AUTOSAR XML (schema 00047)
package /ServiceLayer
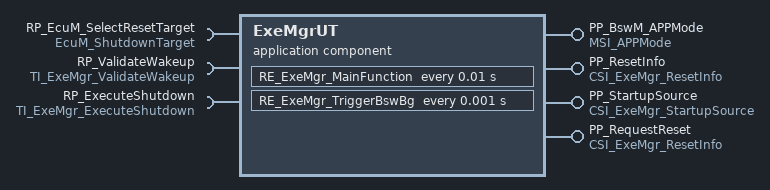
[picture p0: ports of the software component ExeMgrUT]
  application sw component type ExeMgrUT
    require port RP_EcuM_SelectResetTarget: required-interface=EcuM_ShutdownTarget
    4 x provide port:
      PP_BswM_APPMode: provided-interface=MSI_APPMode
      PP_ResetInfo: provided-interface=CSI_ExeMgr_ResetInfo
      PP_StartupSource: provided-interface=CSI_ExeMgr_StartupSource
      PP_RequestReset: provided-interface=CSI_ExeMgr_ResetInfo
    require port RP_ValidateWakeup: required-interface=TI_ExeMgr_ValidateWakeup
    require port RP_ExecuteShutdown: required-interface=TI_ExeMgr_ExecuteShutdown
    behavior IB_ExeMgrUT: data-type-mapping=[DTS_DcmEcuReset, ECUM_STATE_Mapping, ComMModeMapping]
      exclusive area ExeMgr_TriggerBswBg_EXCLUSIVE_AREA
      timing event TE_ExeMgr_MainFunction: start-on-event=RE_ExeMgr_MainFunction, period=0.01
      init event IE_ExeMgr_EvaluateWakeup: start-on-event=RE_ExeMgr_EvaluateWakeup
      init event IE_ExeMgr_EvaluateReset: start-on-event=RE_ExeMgr_EvaluateReset
      operation invoked event OIE_ExeMgr_ExecuteReset: start-on-event=RE_ExeMgr_ExecuteReset, operation=PP_RequestReset.RequestReset
      operation invoked event OIE_ExeMgr_GetLastStartupSource: start-on-event=RE_ExeMgr_StartupSource, operation=PP_StartupSource.GetLastStartupSource
      operation invoked event OIE_ExeMgr_GetLastResetInfo: start-on-event=RE_ExeMgr_ResetInfo, operation=PP_ResetInfo.GetLastResetInfo
      timing event TE_ExeMgr_TriggerBswBg: start-on-event=RE_ExeMgr_TriggerBswBg, period=0.001
      internal trigger occurred event ITE_ExeMgr_GetWakeupSource: start-on-event=RE_ExeMgr_GetWakeupSource, event-source=ITP_GetWakeupSource
      external trigger occurred event ETE_ExeMgr_ExecuteShutdown: start-on-event=RE_ExeMgr_ExecuteShutdown, trigger=RP_ExecuteShutdown.ExecuteShutdown
      implicit-inter-runnable-variables:
        data ExeMgr_StartupSource: type=ExeMgr_StartupSourceType, init-value=STARTUP_SOURCE_NONE:STARTUP_SOURCE_NONE
      10 x runnable:
        RE_ExeMgr_MainFunction: can-be-invoked-concurrently=true, mode-access-point=PP_BswM_APPMode.MDGP_APPMode
          mode switch point MSP_AppMode: mode-group=PP_BswM_APPMode.MDGP_APPMode
          sync call SSCP_SelectShutdownTarget: operation=RP_EcuM_SelectResetTarget.SelectShutdownTarget
          sync call SSCP_SelectShutdownCause: operation=RP_EcuM_SelectResetTarget.SelectShutdownCause
          sync call SSCP_GetShutdownTarget: operation=RP_EcuM_SelectResetTarget.GetShutdownTarget
        RE_ExeMgr_GetWakeupSource
          internal triggering point ITP_GetWakeupSource
          written-local-variables:
            access WLV_StartupSource: accessed-variable=ExeMgr_StartupSource
        RE_ExeMgr_EvaluateWakeup: mode-access-point=PP_BswM_APPMode.MDGP_APPMode
          mode switch point MSP_AppMode: mode-group=PP_BswM_APPMode.MDGP_APPMode
          read-local-variables:
            access RLV_StartupSource: accessed-variable=ExeMgr_StartupSource
          sync call SSCP_SelectShutdownTarget: operation=RP_EcuM_SelectResetTarget.SelectShutdownTarget
          sync call SSCP_SelectShutdownCause: operation=RP_EcuM_SelectResetTarget.SelectShutdownCause
        RE_ExeMgr_ValidateWakeup
          internal triggering point ITP_ValidateWakeupSource
          read-local-variables:
            access RLV_StartupSource: accessed-variable=ExeMgr_StartupSource
        RE_ExeMgr_ExecuteShutdown
        RE_ExeMgr_ExecuteReset
          mode switch point ModeSwitchPoint_0: mode-group=PP_BswM_APPMode.MDGP_APPMode
          sync call SSCP_SelectShutdownTarget: operation=RP_EcuM_SelectResetTarget.SelectShutdownTarget
          sync call SSCP_SelectShutdownCause: operation=RP_EcuM_SelectResetTarget.SelectShutdownCause
        RE_ExeMgr_EvaluateReset
          sync call SSCP_GetLastShutdownTarget: operation=RP_EcuM_SelectResetTarget.GetLastShutdownTarget
        RE_ExeMgr_ResetInfo
          sync call SSCP_GetLastShutdownTarger: operation=RP_EcuM_SelectResetTarget.GetLastShutdownTarget
          sync call SSCP_GettShutdownCause: operation=RP_EcuM_SelectResetTarget.GetShutdownCause
        RE_ExeMgr_StartupSource
          read-local-variables:
            access RLV_StartupSource: accessed-variable=ExeMgr_StartupSource
        RE_ExeMgr_TriggerBswBg: can-enter-exclusive-area=ExeMgr_TriggerBswBg_EXCLUSIVE_AREA, reentrancy-level=SINGLE-CORE-REENTRANT, runs-inside-exclusive-area=ExeMgr_TriggerBswBg_EXCLUSIVE_AREA, can-be-invoked-concurrently=true
package /Pkg_ClientServerInterface
  client server interface CSI_ExeMgr_ResetInfo: is-service=true
    operation GetLastResetInfo
      arg resetReason: type=EcuM_ShutdownCauseType, direction=OUT, server-argument-impl-policy=USE-ARGUMENT-TYPE
      arg resetGroup: type=EcuM_ShutdownModeType, direction=OUT, server-argument-impl-policy=USE-ARGUMENT-TYPE
    operation RequestReset
      arg resetReason: type=EcuM_ShutdownCauseType, direction=IN, server-argument-impl-policy=USE-ARGUMENT-TYPE
      arg resetGroup: type=EcuM_ShutdownModeType, direction=IN, server-argument-impl-policy=USE-ARGUMENT-TYPE
  client server interface CSI_ExeMgr_StartupSource: is-service=true
    operation GetLastStartupSource
      arg startupSource: type=ExeMgr_StartupSourceType, direction=OUT, server-argument-impl-policy=USE-ARGUMENT-TYPE
package /ImplementationDataTypes
  impl type ExeMgr_StartupSourceType: compu {0=STARTUP_SOURCE_NONE, 1=STARTUP_SOURCE_KL15, 2=STARTUP_SOURCE_SWITCH, 4=STARTUP_SOURCE_SLOWCHARGESWITCH, 8=STARTUP_SOURCE_SLOWCHARGECP, 16=STARTUP_SOURCE_REQ4, 32=STARTUP_SOURCE_APLUS, 64=STARTUP_SOURCE_CCWAKE}, implementation-data-type=uint8, type-emitter=RTE
package /Pkg_TriggerInterface
  trigger interface TI_ExeMgr_ValidateWakeup: is-service=true
    trigger ValidateWakeup
  trigger interface TI_ExeMgr_ExecuteShutdown: is-service=true
    trigger ExecuteShutdown
